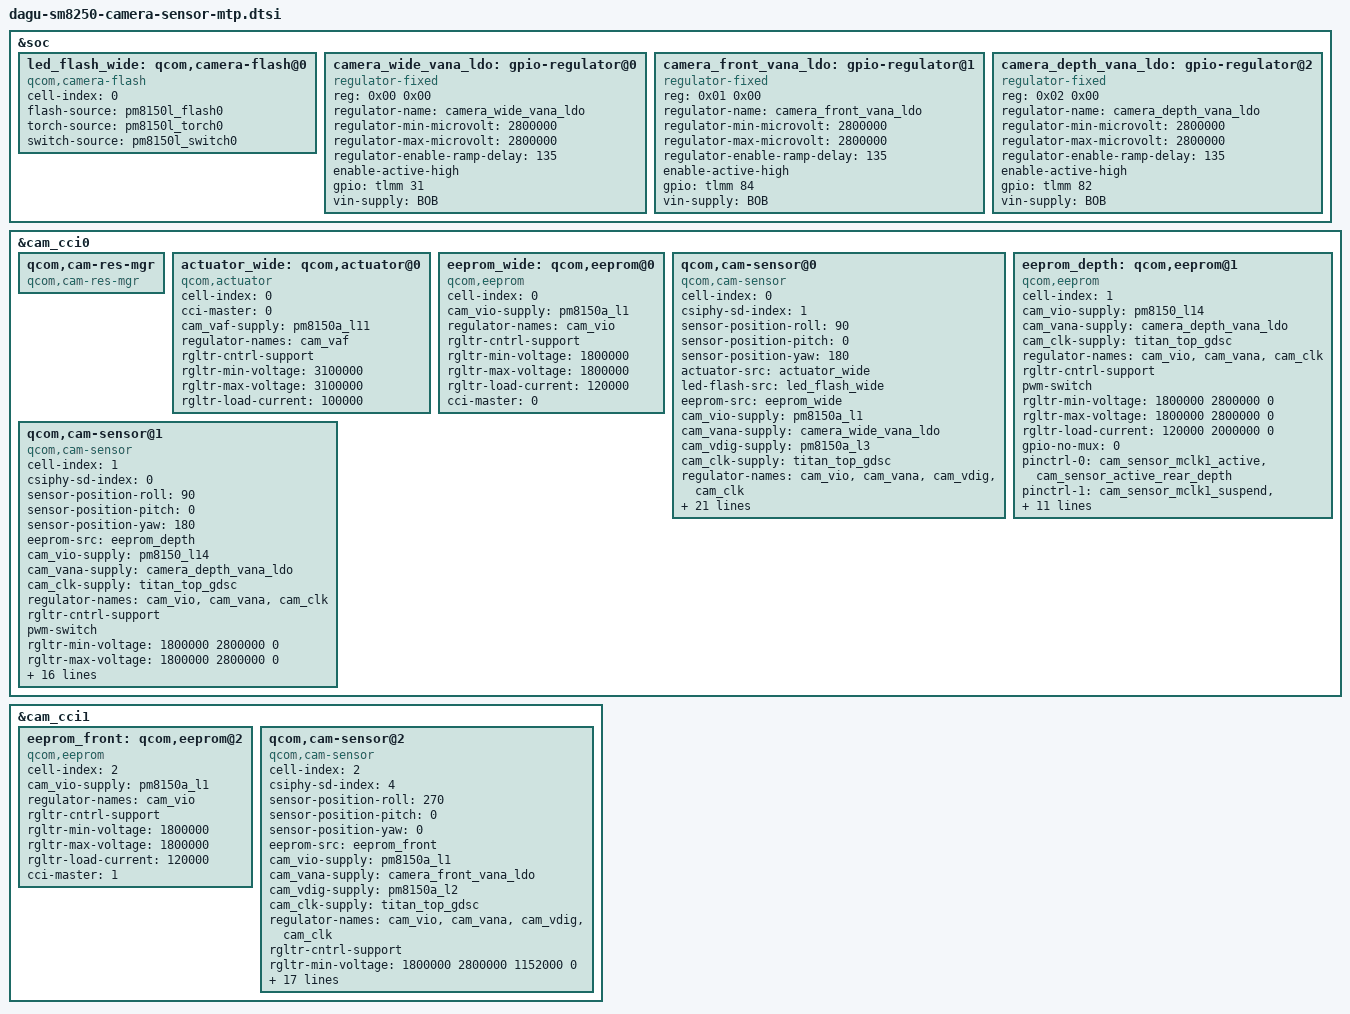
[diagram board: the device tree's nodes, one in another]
#include "dagu-sm8250-camera-board.dtsi"

&soc {
	led_flash_wide: qcom,camera-flash@0 {
		cell-index = <0>;
		compatible = "qcom,camera-flash";
		flash-source = <&pm8150l_flash0>;
		torch-source = <&pm8150l_torch0>;
		switch-source = <&pm8150l_switch0>;
		status = "ok";
	};

    camera_wide_vana_ldo: gpio-regulator@0 {
        compatible = "regulator-fixed";
        reg = <0x00 0x00>;
        regulator-name = "camera_wide_vana_ldo";
        regulator-min-microvolt = <2800000>;
        regulator-max-microvolt = <2800000>;
        regulator-enable-ramp-delay = <135>;
        enable-active-high;
        gpio = <&tlmm 31 0>;
        vin-supply = <&BOB>;
    };
    camera_front_vana_ldo: gpio-regulator@1 {
        compatible = "regulator-fixed";
        reg = <0x01 0x00>;
        regulator-name = "camera_front_vana_ldo";
        regulator-min-microvolt = <2800000>;
        regulator-max-microvolt = <2800000>;
        regulator-enable-ramp-delay = <135>;
        enable-active-high;
        gpio = <&tlmm 84 0>;
 		vin-supply = <&BOB>;
    };
    camera_depth_vana_ldo: gpio-regulator@2 {
        compatible = "regulator-fixed";
        reg = <0x02 0x00>;
        regulator-name = "camera_depth_vana_ldo";
        regulator-min-microvolt = <2800000>;
        regulator-max-microvolt = <2800000>;
        regulator-enable-ramp-delay = <135>;
        enable-active-high;
        gpio = <&tlmm 82 0>;
 		vin-supply = <&BOB>;
    };

};

&cam_cci0 {
	qcom,cam-res-mgr {
		compatible = "qcom,cam-res-mgr";
	};

	actuator_wide: qcom,actuator@0 {
		cell-index = <0>;
		compatible = "qcom,actuator";
		cci-master = <0>;
		cam_vaf-supply = <&pm8150a_l11>;
		regulator-names = "cam_vaf";
		rgltr-cntrl-support;
		rgltr-min-voltage = <3100000>;
		rgltr-max-voltage = <3100000>;
		rgltr-load-current = <100000>;
		status = "ok";
	};

	eeprom_wide: qcom,eeprom@0 {
		cell-index = <0>;
		compatible = "qcom,eeprom";
		cam_vio-supply = <&pm8150a_l1>;
		regulator-names = "cam_vio";
		rgltr-cntrl-support;
		rgltr-min-voltage = <1800000>;
		rgltr-max-voltage = <1800000>;
		rgltr-load-current = <120000>;
		cci-master = <0>;
		status = "ok";
	};

	qcom,cam-sensor@0 {
		cell-index = <0>;
		compatible = "qcom,cam-sensor";
		csiphy-sd-index = <1>;
		sensor-position-roll = <90>;
		sensor-position-pitch = <0>;
		sensor-position-yaw = <180>;
		actuator-src = <&actuator_wide>;
		led-flash-src = <&led_flash_wide>;
		eeprom-src = <&eeprom_wide>;
		cam_vio-supply = <&pm8150a_l1>;
		cam_vana-supply = <&camera_wide_vana_ldo>;//AVDD2.8  BOB+31
		cam_vdig-supply = <&pm8150a_l3>;
		cam_clk-supply = <&titan_top_gdsc>;
		regulator-names = "cam_vio", "cam_vana", "cam_vdig",
			"cam_clk";
		rgltr-cntrl-support;
		pwm-switch;
		rgltr-min-voltage = <1800000 2800000 1104000 0>;//1.1v
		rgltr-max-voltage = <1800000 2800000 1104000 0>;
		rgltr-load-current = <120000 180000 1200000 0>;
		gpio-no-mux = <0>;
		pinctrl-names = "cam_default", "cam_suspend";
		pinctrl-0 = <&cam_sensor_mclk0_active
					&cam_sensor_wide_active>;
		pinctrl-1 = <&cam_sensor_mclk0_suspend
					&cam_sensor_wide_suspend>;
		gpios = <&tlmm 94 0>,
				<&tlmm 93 0>;
		gpio-reset = <1>;
		gpio-req-tbl-num = <0 1>;
		gpio-req-tbl-flags = <1 0>;
		gpio-req-tbl-label = "CAMIF_MCLK0",
							"CAM_RESET0";
		sensor-mode = <0>;
		cci-master = <0>;
		status = "ok";
		use-shared-clk;
		clocks = <&clock_camcc CAM_CC_MCLK0_CLK>;
		clock-names = "cam_clk";
		clock-cntl-level = "turbo";
		clock-rates = <19200000>;
	};

	eeprom_depth: qcom,eeprom@1 {
		cell-index = <1>;
		compatible = "qcom,eeprom";
		cam_vio-supply = <&pm8150_l14>;//
		cam_vana-supply = <&camera_depth_vana_ldo>;
		cam_clk-supply = <&titan_top_gdsc>;
		regulator-names = "cam_vio", "cam_vana", "cam_clk";
		rgltr-cntrl-support;
		pwm-switch;
		rgltr-min-voltage = <1800000 2800000 0>;
		rgltr-max-voltage = <1800000 2800000 0>;
		rgltr-load-current = <120000 2000000 0>;
		gpio-no-mux = <0>;
		pinctrl-names = "cam_default", "cam_suspend";
		pinctrl-0 = <&cam_sensor_mclk1_active
				&cam_sensor_active_rear_depth>;
		pinctrl-1 = <&cam_sensor_mclk1_suspend
				&cam_sensor_suspend_rear_depth>;
		gpios = <&tlmm 95 0>,
			<&tlmm 26 0>;
		gpio-reset = <1>;
		gpio-req-tbl-num = <0 1>;
		gpio-req-tbl-flags = <1 0>;
		gpio-req-tbl-label = "CAMIF_MCLK1",
					"CAM_RESET1";
		sensor-mode = <0>;
		cci-master = <1>;
		status = "ok";
		clocks = <&clock_camcc CAM_CC_MCLK1_CLK>;
		clock-names = "cam_clk";
		clock-cntl-level = "turbo";
		clock-rates = <19200000>;
	};

	qcom,cam-sensor@1 {
		cell-index = <1>;
		compatible = "qcom,cam-sensor";
		csiphy-sd-index = <0>;
		sensor-position-roll = <90>;
		sensor-position-pitch = <0>;
		sensor-position-yaw = <180>;
		eeprom-src = <&eeprom_depth>;
		cam_vio-supply = <&pm8150_l14>;
		cam_vana-supply = <&camera_depth_vana_ldo>;//BOB+82
		cam_clk-supply = <&titan_top_gdsc>;
		regulator-names = "cam_vio", "cam_vana", "cam_clk";
		rgltr-cntrl-support;
		pwm-switch;
		rgltr-min-voltage = <1800000 2800000 0>;
		rgltr-max-voltage = <1800000 2800000 0>;
		rgltr-load-current = <120000 2000000 0>;
		gpio-no-mux = <0>;
		pinctrl-names = "cam_default", "cam_suspend";
		pinctrl-0 = <&cam_sensor_mclk1_active
				&cam_sensor_active_rear_depth>;
		pinctrl-1 = <&cam_sensor_mclk1_suspend
				&cam_sensor_suspend_rear_depth>;
		gpios = <&tlmm 95 0>,
			<&tlmm 26 0>;
		gpio-reset = <1>;
		gpio-req-tbl-num = <0 1>;
		gpio-req-tbl-flags = <1 0>;
		gpio-req-tbl-label = "CAMIF_MCLK1",
					"CAM_RESET1";
		sensor-mode = <0>;
		cci-master = <1>;
		status = "ok";
		clocks = <&clock_camcc CAM_CC_MCLK1_CLK>;
		clock-names = "cam_clk";
		clock-cntl-level = "turbo";
		clock-rates = <19200000>;
	};

};

&cam_cci1 {

	eeprom_front: qcom,eeprom@2 {
		cell-index = <2>;
		compatible = "qcom,eeprom";
		cam_vio-supply = <&pm8150a_l1>;
		regulator-names = "cam_vio";
		rgltr-cntrl-support;
		rgltr-min-voltage = <1800000>;
		rgltr-max-voltage = <1800000>;
		rgltr-load-current = <120000>;
		cci-master = <1>;
		status = "ok";
	};

	qcom,cam-sensor@2 {
		cell-index = <2>;
		compatible = "qcom,cam-sensor";
		csiphy-sd-index = <4>;
		sensor-position-roll = <270>;
		sensor-position-pitch = <0>;
		sensor-position-yaw = <0>;
		eeprom-src = <&eeprom_front>;
		cam_vio-supply = <&pm8150a_l1>;
		cam_vana-supply = <&camera_front_vana_ldo>;//BOB+84
		cam_vdig-supply = <&pm8150a_l2>;
		cam_clk-supply = <&titan_top_gdsc>;
		regulator-names = "cam_vio", "cam_vana", "cam_vdig", "cam_clk";
		rgltr-cntrl-support;
		rgltr-min-voltage = <1800000 2800000 1152000 0>;
		rgltr-max-voltage = <1800000 2800000 1152000 0>;
		rgltr-load-current = <120000 120000 120000 0>;
		gpio-no-mux = <0>;
		pinctrl-names = "cam_default", "cam_suspend";
		pinctrl-0 = <&cam_sensor_mclk3_active
				     &cam_sensor_front_active>;
		pinctrl-1 = <&cam_sensor_mclk3_suspend
				     &cam_sensor_front_suspend>;
		gpios = <&tlmm 97 0>,
			    <&tlmm 109 0>;
		gpio-reset = <1>;
		gpio-req-tbl-num = <0 1>;
		gpio-req-tbl-flags = <1 0>;
		gpio-req-tbl-label = "CAMIF_MCLK3",
					"CAM_RESET3";
		sensor-mode = <0>;
		cci-master = <1>;
		status = "ok";
		clocks = <&clock_camcc CAM_CC_MCLK3_CLK>;
		clock-names = "cam_clk";
		clock-cntl-level = "turbo";
		clock-rates = <19200000>;
	};

};
